# PRU_ICSSG0_PR1_CFG_SLV register map
Vendor: Texas Instruments
Peripheral module from a debugger description file (folder am243x).
Registers are 32-bit, access not given, reset 0x0 unless marked. A register's access mark holds for its fields unless they carry their own. Offsets are as the file gives them; lines under a group give offsets from that group; [hi:lo] are bit positions; {n}, {i} and the like mark numbered series; 'fields as' and 'values as' point back to an identical list; <NAME> marks a mode.

## PRU_ICSSG0_PR1_CFG_SLV
0x00 PR1_CFG__SLV__REGS_pid_reg ro reset 0x6B000103
  [31:0] ICSS_IDVER — Module ID field
0x04 PR1_CFG__SLV__REGS_hwdis_reg ro
  [7:0] HWDIS — HW Disable Observation
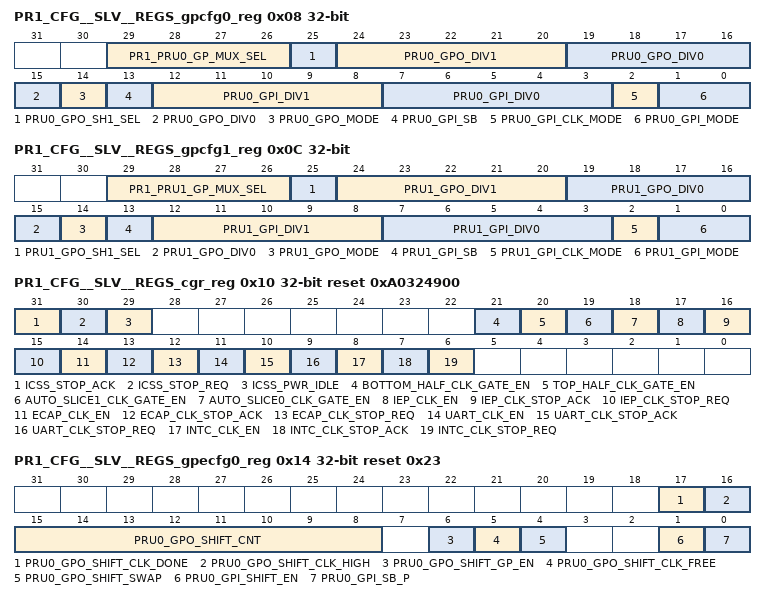
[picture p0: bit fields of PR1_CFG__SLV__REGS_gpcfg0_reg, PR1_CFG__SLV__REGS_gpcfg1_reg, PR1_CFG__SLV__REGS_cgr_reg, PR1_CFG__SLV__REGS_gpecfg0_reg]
0x08 PR1_CFG__SLV__REGS_gpcfg0_reg
  [29:26] PR1_PRU0_GP_MUX_SEL rw
  [25] PRU0_GPO_SH1_SEL ro
  [24:20] PRU0_GPO_DIV1 rw
  [19:15] PRU0_GPO_DIV0 rw
  [14] PRU0_GPO_MODE rw
  [13] PRU0_GPI_SB — (access R/W1TC)
  [12:8] PRU0_GPI_DIV1 rw
  [7:3] PRU0_GPI_DIV0 rw
  [2] PRU0_GPI_CLK_MODE rw
  [1:0] PRU0_GPI_MODE rw
0x0C PR1_CFG__SLV__REGS_gpcfg1_reg
  [29:26] PR1_PRU1_GP_MUX_SEL rw
  [25] PRU1_GPO_SH1_SEL ro
  [24:20] PRU1_GPO_DIV1 rw
  [19:15] PRU1_GPO_DIV0 rw
  [14] PRU1_GPO_MODE rw
  [13] PRU1_GPI_SB — (access R/W1TC)
  [12:8] PRU1_GPI_DIV1 rw
  [7:3] PRU1_GPI_DIV0 rw
  [2] PRU1_GPI_CLK_MODE rw
  [1:0] PRU1_GPI_MODE rw
0x10 PR1_CFG__SLV__REGS_cgr_reg access per field reset 0xA0324900
  [31] ICSS_STOP_ACK rw, [30] ICSS_STOP_REQ ro, [29] ICSS_PWR_IDLE rw, [21] BOTTOM_HALF_CLK_GATE_EN rw, [20] TOP_HALF_CLK_GATE_EN rw, [19] AUTO_SLICE1_CLK_GATE_EN rw, [18] AUTO_SLICE0_CLK_GATE_EN rw, [17] IEP_CLK_EN rw, [16] IEP_CLK_STOP_ACK ro, [15] IEP_CLK_STOP_REQ rw, [14] ECAP_CLK_EN rw, [13] ECAP_CLK_STOP_ACK ro, [12] ECAP_CLK_STOP_REQ rw, [11] UART_CLK_EN rw, [10] UART_CLK_STOP_ACK ro, [9] UART_CLK_STOP_REQ rw, [8] INTC_CLK_EN rw, [7] INTC_CLK_STOP_ACK ro, [6] INTC_CLK_STOP_REQ rw
0x14 PR1_CFG__SLV__REGS_gpecfg0_reg reset 0x23
  [17] PRU0_GPO_SHIFT_CLK_DONE — (access R/W1C)
  [16] PRU0_GPO_SHIFT_CLK_HIGH rw
  [15:8] PRU0_GPO_SHIFT_CNT rw
  [6] PRU0_GPO_SHIFT_GP_EN rw
  [5] PRU0_GPO_SHIFT_CLK_FREE rw
  [4] PRU0_GPO_SHIFT_SWAP rw
  [1] PRU0_GPI_SHIFT_EN rw
  [0] PRU0_GPI_SB_P rw
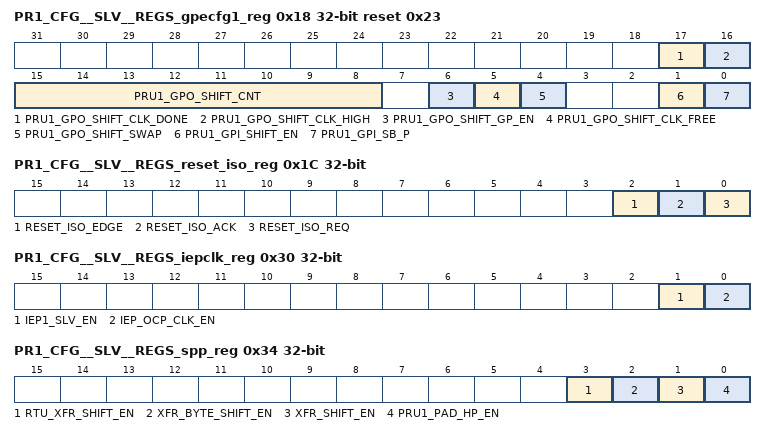
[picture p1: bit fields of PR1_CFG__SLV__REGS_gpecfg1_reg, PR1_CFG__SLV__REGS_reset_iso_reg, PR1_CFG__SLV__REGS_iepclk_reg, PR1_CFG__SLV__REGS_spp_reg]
0x18 PR1_CFG__SLV__REGS_gpecfg1_reg reset 0x23
  [17] PRU1_GPO_SHIFT_CLK_DONE — (access R/W1C)
  [16] PRU1_GPO_SHIFT_CLK_HIGH rw
  [15:8] PRU1_GPO_SHIFT_CNT rw
  [6] PRU1_GPO_SHIFT_GP_EN rw
  [5] PRU1_GPO_SHIFT_CLK_FREE rw
  [4] PRU1_GPO_SHIFT_SWAP rw
  [1] PRU1_GPI_SHIFT_EN rw
  [0] PRU1_GPI_SB_P rw
0x1C PR1_CFG__SLV__REGS_reset_iso_reg
  [2] RESET_ISO_EDGE wo
  [1] RESET_ISO_ACK wo
  [0] RESET_ISO_REQ — (access R/W1C)
0x2C PR1_CFG__SLV__REGS_mii_rt_reg rw reset 0x1
  [0] MII_RT_EVENT_EN
0x30 PR1_CFG__SLV__REGS_iepclk_reg rw
  [1] IEP1_SLV_EN, [0] IEP_OCP_CLK_EN
0x34 PR1_CFG__SLV__REGS_spp_reg rw
  [3] RTU_XFR_SHIFT_EN, [2] XFR_BYTE_SHIFT_EN, [1] XFR_SHIFT_EN, [0] PRU1_PAD_HP_EN
0x3C PR1_CFG__SLV__REGS_core_sync_reg rw
  [0] CORE_VBUSP_SYNC_EN
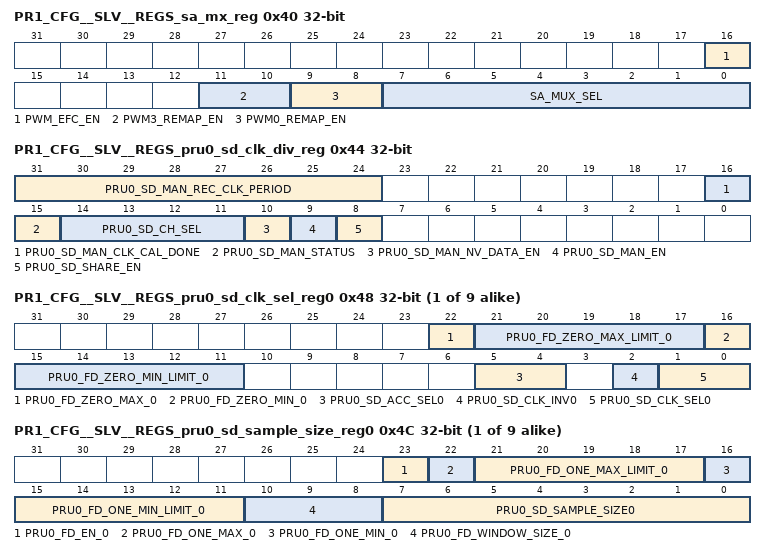
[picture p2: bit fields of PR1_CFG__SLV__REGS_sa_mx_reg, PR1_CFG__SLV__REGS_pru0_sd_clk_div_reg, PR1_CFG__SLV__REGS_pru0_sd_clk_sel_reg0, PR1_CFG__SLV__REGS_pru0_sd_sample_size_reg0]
0x40 PR1_CFG__SLV__REGS_sa_mx_reg rw
  [16] PWM_EFC_EN, [11:10] PWM3_REMAP_EN, [9:8] PWM0_REMAP_EN, [7:0] SA_MUX_SEL
0x44 PR1_CFG__SLV__REGS_pru0_sd_clk_div_reg access per field
  [31:24] PRU0_SD_MAN_REC_CLK_PERIOD ro, [16] PRU0_SD_MAN_CLK_CAL_DONE ro, [15] PRU0_SD_MAN_STATUS ro, [14:11] PRU0_SD_CH_SEL rw, [10] PRU0_SD_MAN_NV_DATA_EN rw, [9] PRU0_SD_MAN_EN rw, [8] PRU0_SD_SHARE_EN rw
{0x48+8i} PR1_CFG__SLV__REGS_pru0_sd_clk_sel_reg{i} (i=0..8)
  [22] PRU0_FD_ZERO_MAX_{i} — (access R/W1C)
  [21:17] PRU0_FD_ZERO_MAX_LIMIT_{i} rw
  [16] PRU0_FD_ZERO_MIN_{i} — (access R/W1C)
  [15:11] PRU0_FD_ZERO_MIN_LIMIT_{i} rw
  [5:4] PRU0_SD_ACC_SEL{i} rw
  [2] PRU0_SD_CLK_INV{i} rw
  [1:0] PRU0_SD_CLK_SEL{i} rw
{0x4C+8i} PR1_CFG__SLV__REGS_pru0_sd_sample_size_reg{i} (i=0..8)
  [23] PRU0_FD_EN_{i} rw
  [22] PRU0_FD_ONE_MAX_{i} — (access R/W1C)
  [21:17] PRU0_FD_ONE_MAX_LIMIT_{i} rw
  [16] PRU0_FD_ONE_MIN_{i} — (access R/W1C)
  [15:11] PRU0_FD_ONE_MIN_LIMIT_{i} rw
  [10:8] PRU0_FD_WINDOW_SIZE_{i} rw
  [7:0] PRU0_SD_SAMPLE_SIZE{i} rw
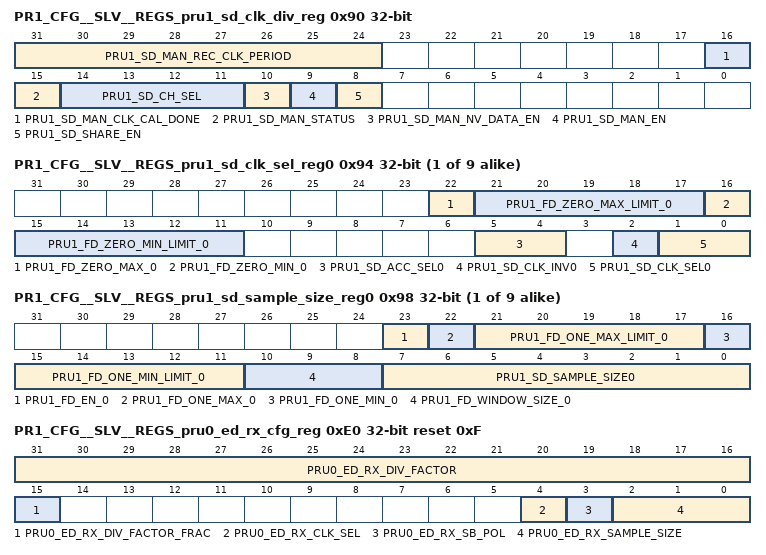
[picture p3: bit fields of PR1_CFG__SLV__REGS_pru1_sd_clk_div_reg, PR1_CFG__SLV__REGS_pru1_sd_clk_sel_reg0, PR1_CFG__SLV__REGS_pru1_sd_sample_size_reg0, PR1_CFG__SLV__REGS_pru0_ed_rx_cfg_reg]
0x90 PR1_CFG__SLV__REGS_pru1_sd_clk_div_reg access per field
  [31:24] PRU1_SD_MAN_REC_CLK_PERIOD ro, [16] PRU1_SD_MAN_CLK_CAL_DONE ro, [15] PRU1_SD_MAN_STATUS ro, [14:11] PRU1_SD_CH_SEL rw, [10] PRU1_SD_MAN_NV_DATA_EN rw, [9] PRU1_SD_MAN_EN rw, [8] PRU1_SD_SHARE_EN rw
{0x94+8i} PR1_CFG__SLV__REGS_pru1_sd_clk_sel_reg{i} (i=0..8)
  [22] PRU1_FD_ZERO_MAX_{i} — (access R/W1C)
  [21:17] PRU1_FD_ZERO_MAX_LIMIT_{i} rw
  [16] PRU1_FD_ZERO_MIN_{i} — (access R/W1C)
  [15:11] PRU1_FD_ZERO_MIN_LIMIT_{i} rw
  [5:4] PRU1_SD_ACC_SEL{i} rw
  [2] PRU1_SD_CLK_INV{i} rw
  [1:0] PRU1_SD_CLK_SEL{i} rw
{0x98+8i} PR1_CFG__SLV__REGS_pru1_sd_sample_size_reg{i} (i=0..8)
  [23] PRU1_FD_EN_{i} rw
  [22] PRU1_FD_ONE_MAX_{i} — (access R/W1C)
  [21:17] PRU1_FD_ONE_MAX_LIMIT_{i} rw
  [16] PRU1_FD_ONE_MIN_{i} — (access R/W1C)
  [15:11] PRU1_FD_ONE_MIN_LIMIT_{i} rw
  [10:8] PRU1_FD_WINDOW_SIZE_{i} rw
  [7:0] PRU1_SD_SAMPLE_SIZE{i} rw
0xE0 PR1_CFG__SLV__REGS_pru0_ed_rx_cfg_reg rw reset 0xF
  [31:16] PRU0_ED_RX_DIV_FACTOR, [15] PRU0_ED_RX_DIV_FACTOR_FRAC, [4] PRU0_ED_RX_CLK_SEL, [3] PRU0_ED_RX_SB_POL, [2:0] PRU0_ED_RX_SAMPLE_SIZE
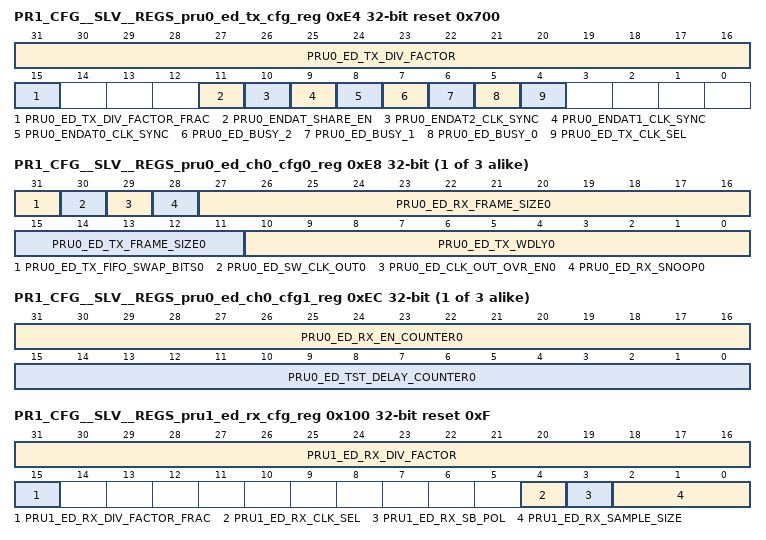
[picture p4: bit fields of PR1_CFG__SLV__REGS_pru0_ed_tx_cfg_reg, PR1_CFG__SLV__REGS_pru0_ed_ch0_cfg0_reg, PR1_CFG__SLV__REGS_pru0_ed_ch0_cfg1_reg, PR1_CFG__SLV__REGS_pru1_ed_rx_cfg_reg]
0xE4 PR1_CFG__SLV__REGS_pru0_ed_tx_cfg_reg access per field reset 0x700
  [31:16] PRU0_ED_TX_DIV_FACTOR rw, [15] PRU0_ED_TX_DIV_FACTOR_FRAC rw, [11] PRU0_ENDAT_SHARE_EN rw, [10] PRU0_ENDAT2_CLK_SYNC ro, [9] PRU0_ENDAT1_CLK_SYNC ro, [8] PRU0_ENDAT0_CLK_SYNC ro, [7] PRU0_ED_BUSY_2 ro, [6] PRU0_ED_BUSY_1 ro, [5] PRU0_ED_BUSY_0 ro, [4] PRU0_ED_TX_CLK_SEL rw
{0xE8+8i} PR1_CFG__SLV__REGS_pru0_ed_ch{i}_cfg0_reg access per field (i=0..2)
  [31] PRU0_ED_TX_FIFO_SWAP_BITS{i} rw, [30] PRU0_ED_SW_CLK_OUT{i} rw, [29] PRU0_ED_CLK_OUT_OVR_EN{i} rw, [28] PRU0_ED_RX_SNOOP{i} ro, [27:16] PRU0_ED_RX_FRAME_SIZE{i} rw, [15:11] PRU0_ED_TX_FRAME_SIZE{i} rw, [10:0] PRU0_ED_TX_WDLY{i} rw
{0xEC+8i} PR1_CFG__SLV__REGS_pru0_ed_ch{i}_cfg1_reg rw (i=0..2)
  [31:16] PRU0_ED_RX_EN_COUNTER{i}, [15:0] PRU0_ED_TST_DELAY_COUNTER{i}
0x100 PR1_CFG__SLV__REGS_pru1_ed_rx_cfg_reg rw reset 0xF
  [31:16] PRU1_ED_RX_DIV_FACTOR, [15] PRU1_ED_RX_DIV_FACTOR_FRAC, [4] PRU1_ED_RX_CLK_SEL, [3] PRU1_ED_RX_SB_POL, [2:0] PRU1_ED_RX_SAMPLE_SIZE
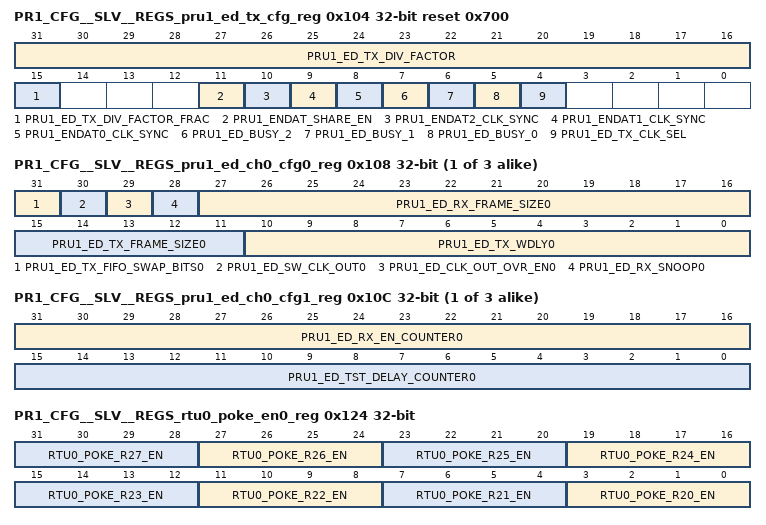
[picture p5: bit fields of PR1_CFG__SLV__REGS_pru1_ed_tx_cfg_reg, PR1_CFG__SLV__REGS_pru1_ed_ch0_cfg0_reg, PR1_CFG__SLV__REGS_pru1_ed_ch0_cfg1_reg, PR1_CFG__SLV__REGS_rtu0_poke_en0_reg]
0x104 PR1_CFG__SLV__REGS_pru1_ed_tx_cfg_reg access per field reset 0x700
  [31:16] PRU1_ED_TX_DIV_FACTOR rw, [15] PRU1_ED_TX_DIV_FACTOR_FRAC rw, [11] PRU1_ENDAT_SHARE_EN rw, [10] PRU1_ENDAT2_CLK_SYNC ro, [9] PRU1_ENDAT1_CLK_SYNC ro, [8] PRU1_ENDAT0_CLK_SYNC ro, [7] PRU1_ED_BUSY_2 ro, [6] PRU1_ED_BUSY_1 ro, [5] PRU1_ED_BUSY_0 ro, [4] PRU1_ED_TX_CLK_SEL rw
{0x108+8i} PR1_CFG__SLV__REGS_pru1_ed_ch{i}_cfg0_reg access per field (i=0..2)
  [31] PRU1_ED_TX_FIFO_SWAP_BITS{i} rw, [30] PRU1_ED_SW_CLK_OUT{i} rw, [29] PRU1_ED_CLK_OUT_OVR_EN{i} rw, [28] PRU1_ED_RX_SNOOP{i} ro, [27:16] PRU1_ED_RX_FRAME_SIZE{i} rw, [15:11] PRU1_ED_TX_FRAME_SIZE{i} rw, [10:0] PRU1_ED_TX_WDLY{i} rw
{0x10C+8i} PR1_CFG__SLV__REGS_pru1_ed_ch{i}_cfg1_reg rw (i=0..2)
  [31:16] PRU1_ED_RX_EN_COUNTER{i}, [15:0] PRU1_ED_TST_DELAY_COUNTER{i}
0x124 PR1_CFG__SLV__REGS_rtu0_poke_en0_reg rw
  [4n-77:4n-80] RTU0_POKE_R{n}_EN (n=20..27)
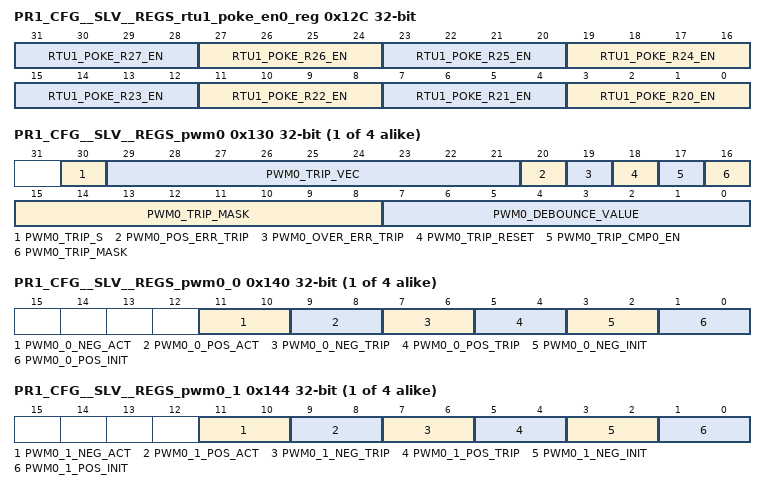
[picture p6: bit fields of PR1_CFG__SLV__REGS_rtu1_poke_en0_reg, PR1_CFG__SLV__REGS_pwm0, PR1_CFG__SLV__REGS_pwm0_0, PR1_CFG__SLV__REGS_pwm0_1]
0x12C PR1_CFG__SLV__REGS_rtu1_poke_en0_reg rw
  [4n-77:4n-80] RTU1_POKE_R{n}_EN (n=20..27)
{0x130+4i} PR1_CFG__SLV__REGS_pwm{i} (i=0..3)
  [30] PWM{i}_TRIP_S — Safety trip status (access R/W1C)
  [29:21] PWM{i}_TRIP_VEC ro — Safety trip trigger cause vector
  [20] PWM{i}_POS_ERR_TRIP rw — SW position saftey error trip
  [19] PWM{i}_OVER_ERR_TRIP rw — SW over safety error trip
  [18] PWM{i}_TRIP_RESET rw — SW reset safety flag
  [17] PWM{i}_TRIP_CMP0_EN rw — CMP0 reset safety trip clear enable
  [16:8] PWM{i}_TRIP_MASK rw — SW mask for safety trip, one hot
  [7:0] PWM{i}_DEBOUNCE_VALUE rw — debounce counter , defines the number of core_clk required for the pulse not to get rejected
{0x140+0xC*i} PR1_CFG__SLV__REGS_pwm{i}_0 rw (i=0..3)
  [11:10] PWM{i}_0_NEG_ACT — Active neg state 00 toggle 01 L 10 H
  [9:8] PWM{i}_0_POS_ACT — Active pos state 00 toggle 01 L 10 H
  [7:6] PWM{i}_0_NEG_TRIP — Safety Trip neg state 00 z 01 L 10 H
  [5:4] PWM{i}_0_POS_TRIP — Safety Trip pos state 00 z 01 L 10 H
  [3:2] PWM{i}_0_NEG_INIT — Initial neg state 00 z 01 L 10 H
  [1:0] PWM{i}_0_POS_INIT — Initial pos state 00 z 01 L 10 H
{0x144+0xC*i} PR1_CFG__SLV__REGS_pwm{i}_1 rw (i=0..3)
  [11:10] PWM{i}_1_NEG_ACT — Active neg state 00 toggle 01 L 10 H
  [9:8] PWM{i}_1_POS_ACT — Active pos state 00 toggle 01 L 10 H
  [7:6] PWM{i}_1_NEG_TRIP — Safety Trip neg state 00 z 01 L 10 H
  [5:4] PWM{i}_1_POS_TRIP — Safety Trip pos state 00 z 01 L 10 H
  [3:2] PWM{i}_1_NEG_INIT — Initial neg state 00 z 01 L 10 H
  [1:0] PWM{i}_1_POS_INIT — Initial pos state 00 z 01 L 10 H
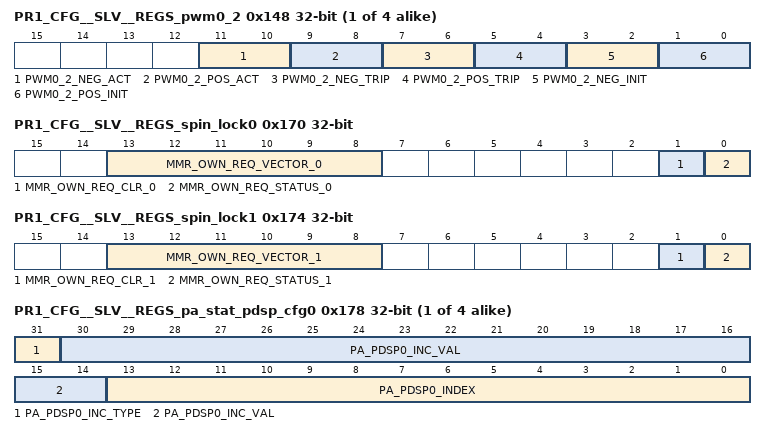
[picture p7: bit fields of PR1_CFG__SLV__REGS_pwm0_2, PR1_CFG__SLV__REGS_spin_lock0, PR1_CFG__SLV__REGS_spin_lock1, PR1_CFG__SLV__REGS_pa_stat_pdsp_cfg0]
{0x148+0xC*i} PR1_CFG__SLV__REGS_pwm{i}_2 rw (i=0..3)
  [11:10] PWM{i}_2_NEG_ACT — Active neg state 00 toggle 01 L 10 H
  [9:8] PWM{i}_2_POS_ACT — Active pos state 00 toggle 01 L 10 H
  [7:6] PWM{i}_2_NEG_TRIP — Safety Trip neg state 00 z 01 L 10 H
  [5:4] PWM{i}_2_POS_TRIP — Safety Trip pos state 00 z 01 L 10 H
  [3:2] PWM{i}_2_NEG_INIT — Initial neg state 00 z 01 L 10 H
  [1:0] PWM{i}_2_POS_INIT — Initial pos state 00 z 01 L 10 H
0x170 PR1_CFG__SLV__REGS_spin_lock0
  [13:8] MMR_OWN_REQ_VECTOR_0 rw — Spin Lock flag Vector
  [1] MMR_OWN_REQ_CLR_0 — Spin Lock Status Clear (access W1C)
  [0] MMR_OWN_REQ_STATUS_0 ro — Spin Lock Status
0x174 PR1_CFG__SLV__REGS_spin_lock1
  [13:8] MMR_OWN_REQ_VECTOR_1 rw — Spin Lock flag Vector
  [1] MMR_OWN_REQ_CLR_1 — Spin Lock Status Clear (access W1C)
  [0] MMR_OWN_REQ_STATUS_1 ro — Spin Lock Status
{0x178+8i} PR1_CFG__SLV__REGS_pa_stat_pdsp_cfg{i} rw (i=0..3)
  [31] PA_PDSP{i}_INC_TYPE, [30:14] PA_PDSP{i}_INC_VAL, [13:0] PA_PDSP{i}_INDEX
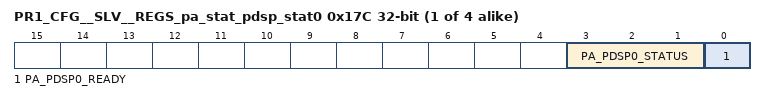
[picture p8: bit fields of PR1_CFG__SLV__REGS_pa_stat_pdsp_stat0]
{0x17C+8i} PR1_CFG__SLV__REGS_pa_stat_pdsp_stat{i} ro (i=0..3)
  [3:1] PA_PDSP{i}_STATUS, [0] PA_PDSP{i}_READY
